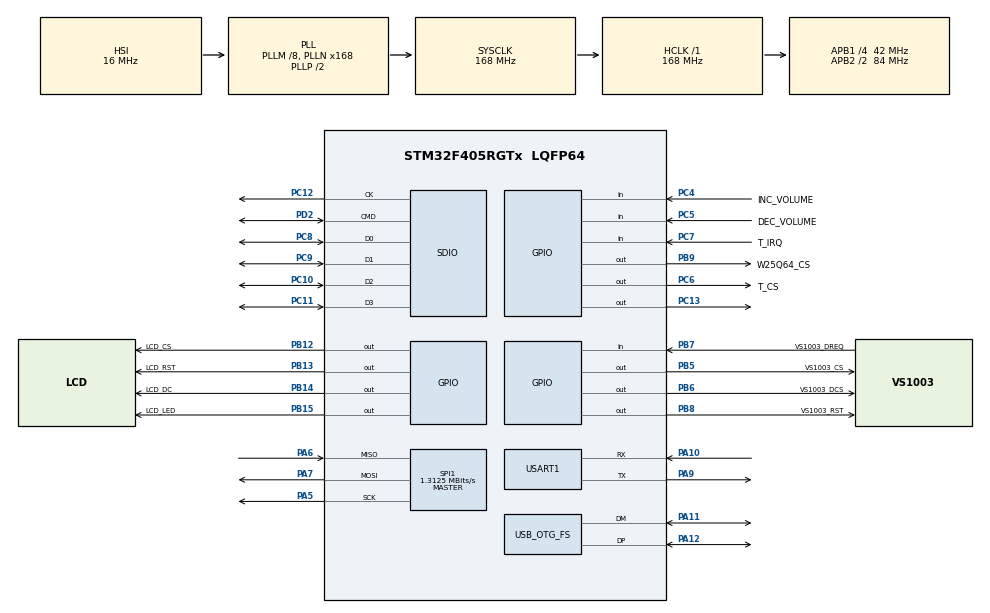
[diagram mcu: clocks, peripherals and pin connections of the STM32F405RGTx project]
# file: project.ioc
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Dma.Request0=SDIO_RX
Dma.Request1=SDIO_TX
Dma.Request2=USART1_RX
Dma.Request3=USART1_TX
Dma.SDIO_RX.0.Direction=DMA_PERIPH_TO_MEMORY
Dma.SDIO_RX.0.FIFOMode=DMA_FIFOMODE_ENABLE
Dma.SDIO_RX.0.FIFOThreshold=DMA_FIFO_THRESHOLD_FULL
Dma.SDIO_RX.0.Instance=DMA2_Stream3
Dma.SDIO_RX.0.MemBurst=DMA_MBURST_INC4
Dma.SDIO_RX.0.MemDataAlignment=DMA_MDATAALIGN_WORD
Dma.SDIO_RX.0.MemInc=DMA_MINC_ENABLE
Dma.SDIO_RX.0.Mode=DMA_PFCTRL
Dma.SDIO_RX.0.PeriphBurst=DMA_PBURST_INC4
Dma.SDIO_RX.0.PeriphDataAlignment=DMA_PDATAALIGN_WORD
Dma.SDIO_RX.0.PeriphInc=DMA_PINC_DISABLE
Dma.SDIO_RX.0.Priority=DMA_PRIORITY_LOW
Dma.SDIO_TX.1.Direction=DMA_MEMORY_TO_PERIPH
Dma.SDIO_TX.1.FIFOMode=DMA_FIFOMODE_ENABLE
Dma.SDIO_TX.1.FIFOThreshold=DMA_FIFO_THRESHOLD_FULL
Dma.SDIO_TX.1.Instance=DMA2_Stream6
Dma.SDIO_TX.1.MemBurst=DMA_MBURST_INC4
Dma.SDIO_TX.1.MemDataAlignment=DMA_MDATAALIGN_WORD
Dma.SDIO_TX.1.MemInc=DMA_MINC_ENABLE
Dma.SDIO_TX.1.Mode=DMA_PFCTRL
Dma.SDIO_TX.1.PeriphBurst=DMA_PBURST_INC4
Dma.SDIO_TX.1.PeriphDataAlignment=DMA_PDATAALIGN_WORD
Dma.SDIO_TX.1.PeriphInc=DMA_PINC_DISABLE
Dma.SDIO_TX.1.Priority=DMA_PRIORITY_LOW
Dma.USART1_RX.2.Direction=DMA_PERIPH_TO_MEMORY
Dma.USART1_RX.2.FIFOMode=DMA_FIFOMODE_DISABLE
Dma.USART1_RX.2.Instance=DMA2_Stream2
Dma.USART1_RX.2.MemDataAlignment=DMA_MDATAALIGN_BYTE
Dma.USART1_RX.2.MemInc=DMA_MINC_ENABLE
Dma.USART1_RX.2.Mode=DMA_NORMAL
Dma.USART1_RX.2.PeriphDataAlignment=DMA_PDATAALIGN_BYTE
Dma.USART1_RX.2.PeriphInc=DMA_PINC_DISABLE
Dma.USART1_RX.2.Priority=DMA_PRIORITY_LOW
Dma.USART1_TX.3.Direction=DMA_MEMORY_TO_PERIPH
Dma.USART1_TX.3.FIFOMode=DMA_FIFOMODE_DISABLE
Dma.USART1_TX.3.Instance=DMA2_Stream7
Dma.USART1_TX.3.MemDataAlignment=DMA_MDATAALIGN_BYTE
Dma.USART1_TX.3.MemInc=DMA_MINC_ENABLE
Dma.USART1_TX.3.Mode=DMA_NORMAL
Dma.USART1_TX.3.PeriphDataAlignment=DMA_PDATAALIGN_BYTE
Dma.USART1_TX.3.PeriphInc=DMA_PINC_DISABLE
Dma.USART1_TX.3.Priority=DMA_PRIORITY_LOW
FATFS._CODE_PAGE=936
FATFS._LFN_UNICODE=1
FATFS._MAX_SS=4096
FATFS._USE_LFN=2
FREERTOS.Tasks01=defaultTask,24,128,StartDefaultTask,Default,NULL,Dynamic,NULL,NULL
FREERTOS.configTOTAL_HEAP_SIZE=24576
Mcu.Family=STM32F4
Mcu.Name=STM32F405RGTx
Mcu.Package=LQFP64
NVIC.DMA2_Stream2_IRQn=true\:5\:0\:false\:false\:true\:true\:false\:true\:true
NVIC.DMA2_Stream3_IRQn=true\:5\:0\:false\:false\:true\:true\:false\:true\:true
NVIC.DMA2_Stream6_IRQn=true\:5\:0\:false\:false\:true\:true\:false\:true\:true
NVIC.DMA2_Stream7_IRQn=true\:5\:0\:false\:false\:true\:true\:false\:true\:true
NVIC.OTG_FS_IRQn=true\:6\:0\:true\:false\:true\:true\:false\:true\:true
NVIC.PriorityGroup=NVIC_PRIORITYGROUP_4
NVIC.SDIO_IRQn=true\:5\:0\:false\:false\:true\:true\:true\:true\:true
NVIC.TIM1_UP_TIM10_IRQn=true\:15\:0\:false\:false\:true\:false\:false\:true\:true
NVIC.TimeBase=TIM1_UP_TIM10_IRQn
NVIC.TimeBaseIP=TIM1
NVIC.USART1_IRQn=true\:5\:0\:true\:false\:true\:true\:true\:true\:true
PA0-WKUP.Mode=SYS_WakeUp0
PA0-WKUP.Signal=SYS_WKUP
PA10.Mode=Asynchronous
PA10.Signal=USART1_RX
PA11.Mode=Device_Only
PA11.Signal=USB_OTG_FS_DM
PA12.Mode=Device_Only
PA12.Signal=USB_OTG_FS_DP
PA13.Mode=Serial_Wire
PA13.Signal=SYS_JTMS-SWDIO
PA14.Mode=Serial_Wire
PA14.Signal=SYS_JTCK-SWCLK
PA5.Mode=Full_Duplex_Master
PA5.Signal=SPI1_SCK
PA6.Mode=Full_Duplex_Master
PA6.Signal=SPI1_MISO
PA7.Mode=Full_Duplex_Master
PA7.Signal=SPI1_MOSI
PA9.Mode=Asynchronous
PA9.Signal=USART1_TX
PB12.GPIO_Label=LCD_CS
PB12.PinState=GPIO_PIN_SET
PB12.Signal=GPIO_Output
PB13.GPIO_Label=LCD_RST
PB13.Signal=GPIO_Output
PB14.GPIO_Label=LCD_DC
PB14.PinState=GPIO_PIN_SET
PB14.Signal=GPIO_Output
PB15.GPIO_Label=LCD_LED
PB15.PinState=GPIO_PIN_SET
PB15.Signal=GPIO_Output
PB5.GPIO_Label=VS1003_CS
PB5.PinState=GPIO_PIN_SET
PB5.Signal=GPIO_Output
PB6.GPIO_Label=VS1003_DCS
PB6.PinState=GPIO_PIN_SET
PB6.Signal=GPIO_Output
PB7.GPIO_Label=VS1003_DREQ
PB7.Signal=GPIO_Input
PB8.GPIO_Label=VS1003_RST
PB8.Signal=GPIO_Output
PB9.GPIO_Label=W25Q64_CS
PB9.PinState=GPIO_PIN_SET
PB9.Signal=GPIO_Output
PC10.GPIO_PuPd=GPIO_PULLUP
PC10.Mode=SD_4_bits_Wide_bus
PC10.Signal=SDIO_D2
PC11.GPIO_PuPd=GPIO_PULLUP
PC11.Mode=SD_4_bits_Wide_bus
PC11.Signal=SDIO_D3
PC12.Mode=SD_4_bits_Wide_bus
PC12.Signal=SDIO_CK
PC13-ANTI_TAMP.Signal=GPIO_Output
PC4.GPIO_Label=INC_VOLUME
PC4.GPIO_PuPd=GPIO_PULLUP
PC4.Signal=GPIO_Input
PC5.GPIO_Label=DEC_VOLUME
PC5.GPIO_PuPd=GPIO_PULLUP
PC5.Signal=GPIO_Input
PC6.GPIO_Label=T_CS
PC6.PinState=GPIO_PIN_SET
PC6.Signal=GPIO_Output
PC7.GPIO_Label=T_IRQ
PC7.Signal=GPIO_Input
PC8.GPIO_PuPd=GPIO_PULLUP
PC8.Mode=SD_4_bits_Wide_bus
PC8.Signal=SDIO_D0
PC9.GPIO_PuPd=GPIO_PULLUP
PC9.Mode=SD_4_bits_Wide_bus
PC9.Signal=SDIO_D1
PD2.Mode=SD_4_bits_Wide_bus
PD2.Signal=SDIO_CMD
PH0-OSC_IN.Mode=HSE-External-Oscillator
PH0-OSC_IN.Signal=RCC_OSC_IN
PH1-OSC_OUT.Mode=HSE-External-Oscillator
PH1-OSC_OUT.Signal=RCC_OSC_OUT
ProjectManager.HeapSize=0x1000
ProjectManager.StackSize=0x2000
ProjectManager.TargetToolchain=MDK-ARM V5.32
RCC.48MHZClocksFreq_Value=48000000
RCC.AHBFreq_Value=168000000
RCC.APB1CLKDivider=RCC_HCLK_DIV4
RCC.APB1Freq_Value=42000000
RCC.APB1TimFreq_Value=84000000
RCC.APB2CLKDivider=RCC_HCLK_DIV2
RCC.APB2Freq_Value=84000000
RCC.APB2TimFreq_Value=168000000
RCC.CortexFreq_Value=168000000
RCC.HCLKFreq_Value=168000000
RCC.HSE_VALUE=8000000
RCC.HSI_VALUE=16000000
RCC.LSE_VALUE=32768
RCC.PLLM=8
RCC.PLLN=168
RCC.PLLQ=7
RCC.PLLSource=RCC_PLLSOURCE_HSI
RCC.SYSCLKFreq_VALUE=168000000
RCC.SYSCLKSource=RCC_SYSCLKSOURCE_PLLCLK
RCC.VCOOutputFreq_Value=336000000
SDIO.ClockDiv=4
SPI1.BaudRatePrescaler=SPI_BAUDRATEPRESCALER_64
SPI1.CalculateBaudRate=1.3125 MBits/s
SPI1.Direction=SPI_DIRECTION_2LINES
SPI1.Mode=SPI_MODE_MASTER
SPI1.VirtualType=VM_MASTER
USART1.VirtualMode=VM_ASYNC
USB_DEVICE.CLASS_NAME_FS=MSC
USB_DEVICE.VirtualMode-MSC_FS=Msc
USB_DEVICE.VirtualModeFS=Msc_FS
USB_OTG_FS.VirtualMode=Device_Only
VP_FATFS_VS_Generic.Mode=User_defined
VP_FATFS_VS_SDIO.Mode=SDIO
VP_FREERTOS_VS_CMSIS_V2.Mode=CMSIS_V2
VP_SYS_VS_tim1.Mode=TIM1
VP_USB_DEVICE_VS_USB_DEVICE_MSC_FS.Mode=MSC_FS
board=custom

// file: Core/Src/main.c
/* USER CODE BEGIN Header */
/**
  ******************************************************************************
  * @file           : main.c
  * @brief          : Main program body
  ******************************************************************************
  * @attention
  *
  * Copyright (c) 2025 STMicroelectronics.
  * All rights reserved.
  *
  * This software is licensed under terms that can be found in the LICENSE file
  * in the root directory of this software component.
  * If no LICENSE file comes with this software, it is provided AS-IS.
  *
  ******************************************************************************
  */
/* USER CODE END Header */
#include "main.h"
#include "cmsis_os.h"
#include "dma.h"
#include "fatfs.h"
#include "sdio.h"
#include "spi.h"
#include "usart.h"
#include "usb_device.h"
#include "gpio.h"

void SystemClock_Config(void);
void MX_FREERTOS_Init(void);
/* USER CODE BEGIN PFP */
void app_main(void);
/* USER CODE END PFP */

int main(void)
{

  /* MCU Configuration--------------------------------------------------------*/

  /* Reset of all peripherals, Initializes the Flash interface and the Systick. */
  HAL_Init();

  /* Configure the system clock */
  SystemClock_Config();

  /* Initialize all configured peripherals */
  MX_GPIO_Init();
  MX_DMA_Init();
  MX_SDIO_SD_Init();
  MX_USART1_UART_Init();
  MX_FATFS_Init();
  MX_SPI1_Init();
  /* USER CODE BEGIN 2 */
  /* ===================== User BEGIN ===================== */
  app_main();
  /* ===================== User END ===================== */
  /* USER CODE END 2 */

  /* Init scheduler */
  osKernelInitialize();  /* Call init function for freertos objects (in cmsis_os2.c) */
  MX_FREERTOS_Init();

  /* Start scheduler */
  osKernelStart();

  /* We should never get here as control is now taken by the scheduler */

  /* Infinite loop */
  while (1)
  {

  }
}

void SystemClock_Config(void)
{
  RCC_OscInitTypeDef RCC_OscInitStruct = {0};
  RCC_ClkInitTypeDef RCC_ClkInitStruct = {0};

  /** Configure the main internal regulator output voltage
  */
  __HAL_RCC_PWR_CLK_ENABLE();
  __HAL_PWR_VOLTAGESCALING_CONFIG(PWR_REGULATOR_VOLTAGE_SCALE1);

  /** Initializes the RCC Oscillators according to the specified parameters
  * in the RCC_OscInitTypeDef structure.
  */
  RCC_OscInitStruct.OscillatorType = RCC_OSCILLATORTYPE_HSI;
  RCC_OscInitStruct.HSIState = RCC_HSI_ON;
  RCC_OscInitStruct.HSICalibrationValue = RCC_HSICALIBRATION_DEFAULT;
  RCC_OscInitStruct.PLL.PLLState = RCC_PLL_ON;
  RCC_OscInitStruct.PLL.PLLSource = RCC_PLLSOURCE_HSI;
  RCC_OscInitStruct.PLL.PLLM = 8;
  RCC_OscInitStruct.PLL.PLLN = 168;
  RCC_OscInitStruct.PLL.PLLP = RCC_PLLP_DIV2;
  RCC_OscInitStruct.PLL.PLLQ = 7;
  if (HAL_RCC_OscConfig(&RCC_OscInitStruct) != HAL_OK)
  {
    Error_Handler();
  }

  /** Initializes the CPU, AHB and APB buses clocks
  */
  RCC_ClkInitStruct.ClockType = RCC_CLOCKTYPE_HCLK|RCC_CLOCKTYPE_SYSCLK
                              |RCC_CLOCKTYPE_PCLK1|RCC_CLOCKTYPE_PCLK2;
  RCC_ClkInitStruct.SYSCLKSource = RCC_SYSCLKSOURCE_PLLCLK;
  RCC_ClkInitStruct.AHBCLKDivider = RCC_SYSCLK_DIV1;
  RCC_ClkInitStruct.APB1CLKDivider = RCC_HCLK_DIV4;
  RCC_ClkInitStruct.APB2CLKDivider = RCC_HCLK_DIV2;

  if (HAL_RCC_ClockConfig(&RCC_ClkInitStruct, FLASH_LATENCY_5) != HAL_OK)
  {
    Error_Handler();
  }
}

void HAL_TIM_PeriodElapsedCallback(TIM_HandleTypeDef *htim)
{
  if (htim->Instance == TIM1)
  {
    HAL_IncTick();
  }
}

void Error_Handler(void)
{
  __disable_irq();
  while (1)
  {
  }
}

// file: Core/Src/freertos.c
/* USER CODE BEGIN Header */
/**
  ******************************************************************************
  * File Name          : freertos.c
  * Description        : Code for freertos applications
  ******************************************************************************
  * @attention
  *
  * Copyright (c) 2025 STMicroelectronics.
  * All rights reserved.
  *
  * This software is licensed under terms that can be found in the LICENSE file
  * in the root directory of this software component.
  * If no LICENSE file comes with this software, it is provided AS-IS.
  *
  ******************************************************************************
  */
/* USER CODE END Header */

#include "FreeRTOS.h"
#include "task.h"
#include "main.h"
#include "cmsis_os.h"

/* USER CODE BEGIN Includes */
#include <stdio.h>
/* USER CODE END Includes */

/* Definitions for defaultTask */
osThreadId_t defaultTaskHandle;
const osThreadAttr_t defaultTask_attributes = {
  .name = "defaultTask",
  .stack_size = 128 * 4,
  .priority = (osPriority_t) osPriorityNormal,
};

void StartDefaultTask(void *argument);

extern void MX_USB_DEVICE_Init(void);
void MX_FREERTOS_Init(void); /* (MISRA C 2004 rule 8.1) */

void MX_FREERTOS_Init(void) {

  /* Create the thread(s) */
  /* creation of defaultTask */
  defaultTaskHandle = osThreadNew(StartDefaultTask, NULL, &defaultTask_attributes);

}

void StartDefaultTask(void *argument)
{
  /* init code for USB_DEVICE */
  MX_USB_DEVICE_Init();
  /* USER CODE BEGIN StartDefaultTask */
  /* USB_DEVICE init moved to file_init() to wait for SD card ready */
  /* Infinite loop */
  for(;;)
  {
    osDelay(1);
  }
  /* USER CODE END StartDefaultTask */
}

/* USER CODE BEGIN Application */

/* FreeRTOS stack overflow hook (configCHECK_FOR_STACK_OVERFLOW is set to 2) */
void vApplicationStackOverflowHook(TaskHandle_t xTask, signed char *pcTaskName)
{
    /* Disable interrupts to prevent the scheduler from running */
    taskDISABLE_INTERRUPTS();

    printf("\r\n");
    printf("****************************************\r\n");
    printf("  STACK OVERFLOW DETECTED!\r\n");
    printf("  Task: %s\r\n", (char *)pcTaskName);
    printf("  Handle: 0x%08lX\r\n", (uint32_t)xTask);
    printf("****************************************\r\n");

    /* Halt here */
    while (1);
}

/* USER CODE END Application */
